# STM32WBA52 register map
File version: 0.1
CPU: CM33 r0p1, little endian, MPU, FPU, 4 interrupt priority bits
Registers are 32-bit, read-write, reset 0x0 unless marked. A register's access mark holds for its fields unless they carry their own. Offsets are from the block's base; [hi:lo] are bit positions; {n}, {i} and the like mark numbered series.

## AES — Advanced encryption standard hardware accelerator
Base 0x420C0000
Same registers: SEC_AES 0x520C0000
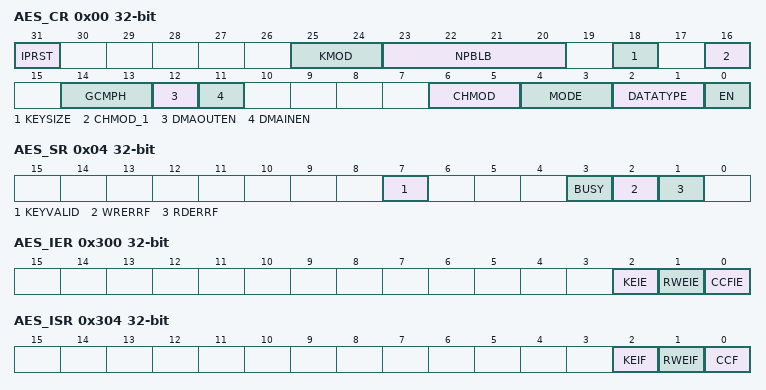
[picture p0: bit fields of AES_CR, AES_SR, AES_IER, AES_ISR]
0x00 AES_CR — AES control register
  [31] IPRST — AES peripheral software reset Setting the bit resets the AES peripheral, putting all registers to their default values, except the IPRST bit itself. Hence, any key-relative data are lost. For this reason, it is recommended to set the bit before handing over the AES to a less secure application. The bit must be low while writing any configuration registers.
  [25:24] KMOD — Key mode selection The bitfield defines how the AES key can be used by the application. KEYSIZE must be correctly initialized when setting KMOD[1:0] different from zero. Others: Reserved Attempts to write the bitfield are ignored when BUSY is set, as well as when EN is set before the write access and it is not cleared by that write access.
    0=Normal key mode. Key registers are freely usable.; 2=Shared key mode. If shared key mode is properly initialized in SAES peripheral, the AES peripheral automatically loads its key registers with the data stored in the SAES key registers. The key value is available in AES key registers when BUSY bit is cleared and KEYVALID is set in the AES_SR register. Key error flag KEIF is set otherwise in the AES_ISR register.
  [23:20] NPBLB — Number of padding bytes in last block This padding information must be filled by software before processing the last block of GCM payload encryption or CCM payload decryption, otherwise authentication tag computation is incorrect. ...
    0=All bytes are valid (no padding); 1=Padding for the last LSB byte; 15=Padding for the 15 LSB bytes of last block
  [18] KEYSIZE — Key size selection This bitfield defines the key length in bits of the key used by AES. Attempts to write the bit are ignored when BUSY is set, as well as when the EN is set before the write access and it is not cleared by that write access.
    0=128-bit; 1=256-bit
  [16] CHMOD_1 — CHMOD[2]
  [14:13] GCMPH — GCM or CCM phase selection This bitfield selects the phase, applicable only with GCM, GMAC or CCM chaining modes. This bitfield has no effect if GCM, GMAC or CCM algorithm is not selected with CHMOD[2:0].
    0=Initialization phase; 1=Header phase; 2=Payload phase; 3=Final phase
  [12] DMAOUTEN — DMA output enable When this bit is set, DMA requests are automatically generated by the peripheral during the output data phase. Setting this bit is ignored when MODE[1:0] is at 01 (key derivation).
    0=DMA for outgoing data transfer is disabled; 1=DMA for outgoing data transfer is enabled
  [11] DMAINEN — DMA input enable When this bit is set, DMA requests are automatically generated by the peripheral during the input data phase. Setting this bit is ignored when MODE[1:0] is at 01 (key derivation).
    0=DMA for incoming data transfer is disabled; 1=DMA for incoming data transfer is enabled
  [6:5] CHMOD — CHMOD[1:0]: Chaining mode This bitfield selects the AES chaining mode: others: Reserved Attempts to write the bitfield are ignored when BUSY is set, as well as when EN is set before the write access and it is not cleared by that write access.
    0=Electronic codebook (ECB); 1=Cipher-block chaining (CBC); 2=Counter mode (CTR); 3=Galois counter mode (GCM) and Galois message authentication code (GMAC); 4=Counter with CBC-MAC (CCM)
  [4:3] MODE — Operating mode This bitfield selects the AES operating mode: Attempts to write the bitfield are ignored when BUSY is set, as well as when EN is set before the write access and it is not cleared by that write access.
    0=Encryption; 1=Key derivation (or key preparation), for ECB/CBC decryption only; 2=Decryption
  [2:1] DATATYPE — Data type This bitfield defines the format of data written in the AES_DINR register or read from the AES_DOUTR register, through selecting the mode of data swapping. This swapping is defined in Section�23.4.17: AES data registers and data swapping. Attempts to write the bitfield are ignored when BUSY is set, as well as when EN is set before the write access and it is not cleared by that write access.
    0=No swapping (32-bit data); 1=Half-word swapping (16-bit data); 2=Byte swapping (8-bit data); 3=Bit-level swapping
  [0] EN — Enable This bit enables/disables the AES peripheral. At any moment, clearing then setting the bit re-initializes the AES peripheral. This bit is automatically cleared by hardware upon the completion of the key preparation (MODE[1:0] at 01) and upon the completion of GCM/GMAC/CCM initialization phase. The bit cannot be set as long as KEYVALID�=�0.
    0=Disable; 1=Enable
0x04 AES_SR ro — AES status register
  [7] KEYVALID — Key valid flag This bit is set by hardware when the key of size defined by KEYSIZE is loaded in AES_KEYRx key registers. The EN bit can only be set when KEYVALID is set. In normal mode when KEYSEL[2:0] is at 000, the key must be written in the key registers in the correct sequence, otherwise the KEIF flag is set and KEYVALID remains cleared. When KEYSEL[2:0] is different from zero, the BUSY flag is automatically set by AES. When the key is loaded successfully, BUSY is cleared and KEYVALID set. Upon an error, KEIF is set, BUSY cleared and KEYVALID remains cleared. If set, KEIF must be cleared through the AES_ICR register, otherwise KEYVALID cannot be set. See the KEIF flag description for more details. For further information on key loading, refer to Section�23.4.18: AES key registers.
    0=Key not valid; 1=Key valid
  [3] BUSY — Busy This flag indicates whether AES is idle or busy. AES is flagged as idle when disabled or when the last processing is completed. AES is flagged as busy when processing a block data, preparing a key (ECB or CBC decryption only), or transferring a shared key from SAES peripheral. When GCM encryption is selected, this flag must be at zero before suspending current process to manage a higher-priority message.
    0=Idle; 1=Busy
  [2] WRERRF — Write error flag This bit is set when an unexpected write to the AES_DINR register occurred. When set WRERRF bit has no impact on the AES operations. This flag is cleared by setting the RWEIF bit in AES_ICR register. If RWEIE bit is set in AES_IER register an interrupt is generated when WRERRF is set. It is cleared by setting the RWEIF bit of the AES_ICR register.
    0=No error; 1=Unexpected write to AES_DINR register occurred during computation or data output phase
  [1] RDERRF — Read error flag This bit is set when an unexpected read to the AES_DOUTR register occurred. When set RDERRF bit has no impact on the AES operations. This flag is cleared by setting the RWEIF bit in AES_ICR register. If RWEIE bit is set in AES_IER register an interrupt is generated when RDERRF is set. It is cleared by setting the RWEIF bit of the AES_ICR register.
    0=No error; 1=Unexpected read to AES_DOUTR register occurred during computation or data input phase
0x08 AES_DINR wo — AES data input register
  [31:0] DIN — Input data word A four-fold sequential write to this bitfield during the Input phase results in writing a complete 16-bytes block of input data to the AES peripheral. From the first to the fourth write, the corresponding data weights are [127:96], [95:64], [63:32], and [31:0]. Upon each write, the data from the 32-bit input buffer are handled by the data swap block according to the DATATYPE[1:0] bitfield, then written into the AES core 16-bytes input buffer. Reads return zero.
0x0C AES_DOUTR ro — AES data output register
  [31:0] DOUT — Output data word This read-only bitfield fetches a 32-bit output buffer. A four-fold sequential read of this bitfield, upon the computation completion (CCF flag set), virtually reads a complete 16-byte block of output data from the AES peripheral. Before reaching the output buffer, the data produced by the AES core are handled by the data swap block according to the DATATYPE[1:0] bitfield. Data weights from the first to the fourth read operation are: [127:96], [95:64], [63:32], and [31:0].
0x10 AES_KEYR0 wo — AES key register 0
  [31:0] KEY — Cryptographic key, bits [31:0] This write-only bitfield contains the bits [31:0] of the AES encryption or decryption key, depending on the operating mode MODE[1:0] in AES_CR. The AES_KEYRx registers may be written only when KEYSIZE value is correct and when the AES peripheral is disabled (EN bit of the AES_CR register cleared). A special writing sequence is also required, as described in KEYVALID bit of the AES_SR register. Note that, if KMOD[1:0] is at 10 (shared key), the key is directly loaded from SAES peripheral to AES_KEYRx registers (hence writes to key register is ignored and KEIF is set). When KEYVALID is set a write to this register clears KEYVALID if AES is disabled.
{0x10+4i} AES_KEYR{i} wo (i=1..3) — AES key register {i}
  [31:0] KEY — Cryptographic key, bits [{32i+31}:{32i}] Refer to the AES_KEYR0 register for description of the KEY[255:0] bitfield. When KEYVALID is set in AES_SR a write to this register clears KEYVALID if EN is cleared in AES_CR.
0x20 AES_IVR0 — AES initialization vector register 0
  [31:0] IVI — Initialization vector input, bits [31:0] AES_IVRx registers store the 128-bit initialization vector or the nonce, depending on the chaining mode selected. This value is updated by the AES core after each computation round (when applicable). Write to this register is ignored when EN bit is set in AES_SR register
{0x20+4i} AES_IVR{i} (i=1..3) — AES initialization vector register {i}
  [31:0] IVI — Initialization vector input, bits [{32i+31}:{32i}] Refer to the AES_IVR0 register for description of the IVI[128:0] bitfield.
{0x20+4i} AES_KEYR{i} wo (i=4..7) — AES key register {i}
  [31:0] KEY — Cryptographic key, bits [{32i+31}:{32i}] Refer to the AES_KEYR0 register for description of the KEY[255:0] bitfield. Writing to this register has no effect when key size is 128-bit (KEYSIZE=0). When KEYVALID is set in AES_SR a write to this register clears KEYVALID if EN is cleared in AES_CR.
{0x40+4i} AES_SUSPR{i} (i=0..7) — AES suspend registers
  [31:0] SUSP — Suspend data AES_SUSPRx registers contain the complete internal register states of the AES when the GCM, GMAC or CCM processing of the current task is suspended to process a higher-priority task. Refer to Section�23.4.8: AES suspend and resume operations for more details. Read to this register returns zero when EN bit is cleared in AES_SR register. AES_SUSPRx registers are not used in other chaining modes than GCM, GMAC or CCM.
0x300 AES_IER — AES interrupt enable register
  [all] fields
    0=Disabled (masked); 1=Enabled (not masked)
  [2] KEIE — Key error interrupt enable This bit enables or disables (masks) the AES interrupt generation when KEIF (key error flag) is set.
  [1] RWEIE — Read or write error interrupt enable This bit enables or disables (masks) the AES interrupt generation when RWEIF (read and/or write error flag) is set.
  [0] CCFIE — Computation complete flag interrupt enable This bit enables or disables (masks) the AES interrupt generation when CCF (computation complete flag) is set.
0x304 AES_ISR ro — AES interrupt status register
  [2] KEIF — Key error interrupt flag This read-only bit is set by hardware when key information failed to load into key registers. Setting the corresponding bit of the AES_ICR register clears the KEIF and generates interrupt if the KEIE bit of the AES_IER register is set. KEIF is triggered upon any of the following errors: AES_KEYRx register write does not respect the correct order. (For KEYSIZE�=�0, AES_KEYR0 then AES_KEYR1 then AES_KEYR2 then AES_KEYR3 register, or reverse. For KEYSIZE set, AES_KEYR0 then AES_KEYR1 then AES_KEYR2 then AES_KEYR3 then AES_KEYR4 then AES_KEYR5 then AES_KEYR6 then AES_KEYR7, or reverse). KEIF must be cleared by the application software, otherwise KEYVALID cannot be set.
    0=No key error detected; 1=Key information failed to load into key registers
  [1] RWEIF — Read or write error interrupt flag This read-only bit is set by hardware when a RDERRF or a WRERRF error flag is set in the AES_SR register. RWEIF bit is cleared when application sets the corresponding bit of AES_ICR register. An interrupt is generated if the RWEIE bit has been previously set in the AES_IER register. This flags has no meaning when key derivation mode is selected.
    0=No read or write error detected; 1=Read or write error detected (see AES_SR register for details)
  [0] CCF — Computation complete flag This flag indicates whether the computation is completed. It is significant only when the DMAOUTEN bit is cleared, and it may stay high when DMAOUTEN is set. CCF bit is cleared when application sets the corresponding bit of AES_ICR register. An interrupt is generated if the CCFIE bit has been previously set in the AES_IER register.
    0=Not completed; 1=Completed
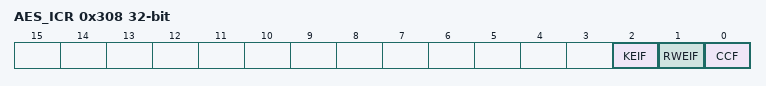
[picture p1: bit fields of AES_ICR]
0x308 AES_ICR wo — AES interrupt clear register
  [2] KEIF — Key error interrupt flag clear Setting this bit clears the KEIF status bit of the AES_ISR register.
  [1] RWEIF — Read or write error interrupt flag clear Setting this bit clears the RWEIF status bit of the AES_ISR register, and clears both RDERRF and WRERRF flags in the AES_SR register.
  [0] CCF — Computation complete flag clear Setting this bit clears the CCF status bit of the AES_ISR register.
